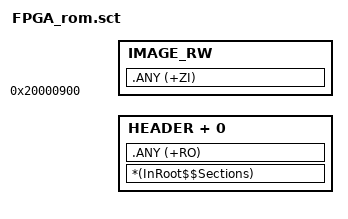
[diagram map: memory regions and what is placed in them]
; *************************************************************
; *** Scatter-Loading Description File generated by uVision ***
; *************************************************************

SOC 0x00000000 0x20000  ; 128KB
{
    STARTUP + 0
    {
        *(VECTOR_TABLE, +First)
    }

    HEADER + 0 FIXED                ;should always start from offset 0xC0
    {
        *(IMAGE_HEADER, +First)
    }

;    BLE_JUMP_TABLE 0x00000200 FIXED 0x400
;    {
;        .ANY (jump_table_mem_area)
;    }

    IMAGE_RO + 0
    {
        *(InRoot$$Sections)
        .ANY (+RO)
    }

    IMAGE_RW 0x20000900      ; fixed address after BootROM BLE_ZI
    {
        *(RO_IN_SYS_RAM)
        ;*(RW_IN_SYS_RAM)
        ;clock.o (+RO, +RW, +ZI)
        .ANY (+RW)
    }

    IMAGE_ZI + 0
    {
        ;*(ZI_IN_SYS_RAM)
        .ANY (+ZI)
    }
}

